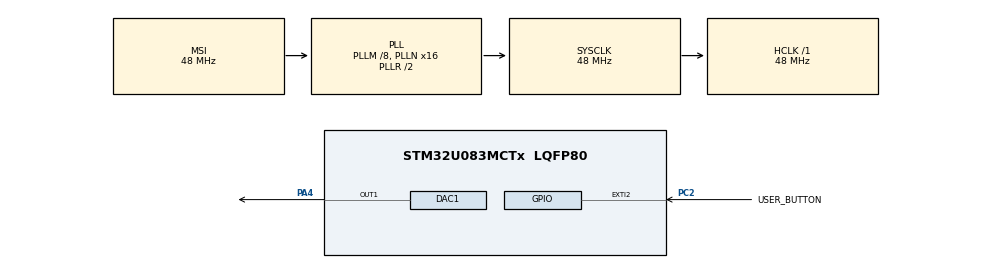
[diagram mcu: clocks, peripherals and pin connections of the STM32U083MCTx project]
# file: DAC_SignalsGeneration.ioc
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DAC1.DAC_Trigger-DAC_OUT1=DAC_TRIGGER_T1_TRGO
Dma.DAC1_CH1.0.Direction=DMA_MEMORY_TO_PERIPH
Dma.DAC1_CH1.0.EventEnable=DISABLE
Dma.DAC1_CH1.0.Instance=DMA1_Channel3
Dma.DAC1_CH1.0.MemDataAlignment=DMA_MDATAALIGN_BYTE
Dma.DAC1_CH1.0.MemInc=DMA_MINC_ENABLE
Dma.DAC1_CH1.0.Mode=DMA_CIRCULAR
Dma.DAC1_CH1.0.PeriphDataAlignment=DMA_PDATAALIGN_BYTE
Dma.DAC1_CH1.0.PeriphInc=DMA_PINC_DISABLE
Dma.DAC1_CH1.0.Polarity=HAL_DMAMUX_REQ_GEN_RISING
Dma.DAC1_CH1.0.Priority=DMA_PRIORITY_LOW
Dma.DAC1_CH1.0.RequestNumber=1
Dma.DAC1_CH1.0.SignalID=NONE
Dma.DAC1_CH1.0.SyncEnable=DISABLE
Dma.DAC1_CH1.0.SyncPolarity=HAL_DMAMUX_SYNC_NO_EVENT
Dma.DAC1_CH1.0.SyncRequestNumber=1
Dma.DAC1_CH1.0.SyncSignalID=NONE
Dma.Request0=DAC1_CH1
Mcu.Family=STM32U0
Mcu.Name=STM32U083MCTx
Mcu.Package=LQFP80
NVIC.DMA1_Channel2_3_IRQn=true\:0\:0\:false\:false\:true\:true\:true\:true
NVIC.EXTI2_3_IRQn=true\:0\:0\:false\:false\:true\:true\:true\:true
NVIC.PriorityGroup=NVIC_PRIORITYGROUP_2
PA4.Signal=COMP_DAC11_group
PC2.GPIO_Label=USER_BUTTON
PC2.GPIO_ModeDefaultEXTI=GPIO_MODE_IT_FALLING
PC2.GPIO_PuPd=GPIO_PULLUP
PC2.Signal=GPXTI2
ProjectManager.HeapSize=0x200
ProjectManager.StackSize=0x400
ProjectManager.TargetToolchain=EWARM V9.20
RCC.ADCFreq_Value=48000000
RCC.AHBFreq_Value=48000000
RCC.CortexFreq_Value=48000000
RCC.HCLKFreq_Value=48000000
RCC.HSE_VALUE=4000000
RCC.HSI48_VALUE=48000000
RCC.HSI_VALUE=16000000
RCC.LSE_VALUE=32768
RCC.MSIClockRangeVal=RCC_MSIRANGE_11
RCC.MSI_VALUE=48000000
RCC.PLLM=RCC_PLLM_DIV8
RCC.PLLN=16
RCC.PLLSourceVirtual=RCC_PLLSOURCE_MSI
RCC.SYSCLKFreq_VALUE=48000000
RCC.SYSCLKSource=RCC_SYSCLKSOURCE_PLLCLK
RCC.USBFreq_Value=48000000
RCC.VCOOutputFreq_Value=96000000
SH.COMP_DAC11_group.0=DAC1_OUT1,DAC_OUT1
TIM1.AutoReloadPreload=TIM_AUTORELOAD_PRELOAD_DISABLE
TIM1.CounterMode=TIM_COUNTERMODE_UP
TIM1.Period=0x7ff
TIM1.Prescaler=0
TIM1.TIM_MasterOutputTrigger=TIM_TRGO_UPDATE
VP_PWR_VS_SECSignals.Mode=Security/Privilege
VP_TIM1_VS_ClockSourceINT.Mode=Internal
board=custom

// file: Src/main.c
/* USER CODE BEGIN Header */
/**
  ******************************************************************************
  * @file    DAC/DAC_SignalsGeneration/Src/main.c
  * @author  MCD Application Team
  * @brief   This example provides a short description of how to use the DAC
  *          peripheral to generate several signals.
  ******************************************************************************
   * @attention
  *
  * Copyright (c) 2023 STMicroelectronics.
  * All rights reserved.
  *
  * This software is licensed under terms that can be found in the LICENSE file
  * in the root directory of this software component.
  * If no LICENSE file comes with this software, it is provided AS-IS.
  *
  ******************************************************************************
  */
/* USER CODE END Header */
#include "main.h"

DAC_HandleTypeDef hdac1;
DMA_HandleTypeDef hdma_dac1_ch1;

TIM_HandleTypeDef htim1;

/* USER CODE BEGIN PV */
__IO uint8_t ubKeyPressed = SET;
__IO uint8_t ubSelectedWavesForm = 1;
const uint8_t aEscalator8bit[6] = {0x0, 0x33, 0x66, 0x99, 0xCC, 0xFF};
/* USER CODE END PV */

void SystemClock_Config(void);
static void MX_GPIO_Init(void);
static void MX_DMA_Init(void);
static void MX_DAC1_Init(void);
static void MX_TIM1_Init(void);
/* USER CODE BEGIN PFP */
static void DAC_Ch1_TriangleConfig(void);
static void DAC_Ch1_EscalatorConfig(void);
/* USER CODE END PFP */

int main(void)
{
  /* USER CODE BEGIN 1 */

  /* STM32U0xx HAL library initialization:
       - Configure the Flash prefetch
       - Systick timer is configured by default as source of time base, but user
         can eventually implement his proper time base source (a general purpose
         timer for example or other time source), keeping in mind that Time base
         duration should be kept 1ms since PPP_TIMEOUT_VALUEs are defined and
         handled in milliseconds basis.
       - Set NVIC Group Priority to 4
       - Low Level Initialization
     */
  /* USER CODE END 1 */

  /* MCU Configuration--------------------------------------------------------*/

  /* Reset of all peripherals, Initializes the Flash interface and the Systick. */
  HAL_Init();

  /* Configure the system clock */
  SystemClock_Config();

  /* Initialize all configured peripherals */
  MX_GPIO_Init();
  MX_DMA_Init();
  MX_DAC1_Init();
  MX_TIM1_Init();
  /* USER CODE BEGIN 2 */
  /* Configure LED5 */
  BSP_LED_Init(LED5);

  /* Configure Joystick Sel push-button in Interrupt mode */
  BSP_PB_Init(BUTTON_USER, BUTTON_MODE_EXTI);

  /* Enable TIM peripheral counter */
  HAL_TIM_Base_Start(&htim1);
  /* USER CODE END 2 */

  /* Infinite loop */
  /* USER CODE BEGIN WHILE */
  while (1)
  {
    /* If the Key is pressed */
    if (ubKeyPressed != RESET)
    {
   HAL_DAC_DeInit(&hdac1);

      /* select waves forms according to the Joystick Sel push-button status */
      if (ubSelectedWavesForm == 1)
      {
        /* The triangle wave has been selected */

        /* Triangle Wave generator -------------------------------------------*/
        DAC_Ch1_TriangleConfig();
      }
      else
      {
        /* The escalator wave has been selected */

        /* Escalator Wave generator -------------------------------------------*/
        DAC_Ch1_EscalatorConfig();
      }

      ubKeyPressed = RESET;
    }
    /* USER CODE END WHILE */

  }
}

void SystemClock_Config(void)
{
  RCC_OscInitTypeDef RCC_OscInitStruct = {0};
  RCC_ClkInitTypeDef RCC_ClkInitStruct = {0};

  /** Configure the main internal regulator output voltage
  */
  HAL_PWREx_ControlVoltageScaling(PWR_REGULATOR_VOLTAGE_SCALE1);

  /** Initializes the RCC Oscillators according to the specified parameters
  * in the RCC_OscInitTypeDef structure.
  */
  RCC_OscInitStruct.OscillatorType = RCC_OSCILLATORTYPE_MSI;
  RCC_OscInitStruct.MSIState = RCC_MSI_ON;
  RCC_OscInitStruct.MSICalibrationValue = RCC_MSICALIBRATION_DEFAULT;
  RCC_OscInitStruct.MSIClockRange = RCC_MSIRANGE_11;
  RCC_OscInitStruct.PLL.PLLState = RCC_PLL_ON;
  RCC_OscInitStruct.PLL.PLLSource = RCC_PLLSOURCE_MSI;
  RCC_OscInitStruct.PLL.PLLM = RCC_PLLM_DIV8;
  RCC_OscInitStruct.PLL.PLLN = 16;
  RCC_OscInitStruct.PLL.PLLP = RCC_PLLP_DIV2;
  RCC_OscInitStruct.PLL.PLLQ = RCC_PLLQ_DIV2;
  RCC_OscInitStruct.PLL.PLLR = RCC_PLLR_DIV2;
  if (HAL_RCC_OscConfig(&RCC_OscInitStruct) != HAL_OK)
  {
    Error_Handler();
  }

  /** Initializes the CPU, AHB and APB buses clocks
  */
  RCC_ClkInitStruct.ClockType = RCC_CLOCKTYPE_HCLK|RCC_CLOCKTYPE_SYSCLK
                              |RCC_CLOCKTYPE_PCLK1;
  RCC_ClkInitStruct.SYSCLKSource = RCC_SYSCLKSOURCE_PLLCLK;
  RCC_ClkInitStruct.AHBCLKDivider = RCC_SYSCLK_DIV1;
  RCC_ClkInitStruct.APB1CLKDivider = RCC_HCLK_DIV1;

  if (HAL_RCC_ClockConfig(&RCC_ClkInitStruct, FLASH_LATENCY_1) != HAL_OK)
  {
    Error_Handler();
  }
}

static void MX_DAC1_Init(void)
{

  DAC_ChannelConfTypeDef sConfig = {0};

  /** DAC Initialization
  */
  hdac1.Instance = DAC1;
  if (HAL_DAC_Init(&hdac1) != HAL_OK)
  {
    Error_Handler();
  }

  /** DAC channel OUT1 config
  */
  sConfig.DAC_SampleAndHold = DAC_SAMPLEANDHOLD_DISABLE;
  sConfig.DAC_Trigger = DAC_TRIGGER_T1_TRGO;
  sConfig.DAC_OutputBuffer = DAC_OUTPUTBUFFER_DISABLE;
  sConfig.DAC_ConnectOnChipPeripheral = DAC_CHIPCONNECT_EXTERNAL;
  sConfig.DAC_UserTrimming = DAC_TRIMMING_FACTORY;
  if (HAL_DAC_ConfigChannel(&hdac1, &sConfig, DAC_CHANNEL_1) != HAL_OK)
  {
    Error_Handler();
  }

}

static void MX_TIM1_Init(void)
{

  TIM_ClockConfigTypeDef sClockSourceConfig = {0};
  TIM_MasterConfigTypeDef sMasterConfig = {0};

  htim1.Instance = TIM1;
  htim1.Init.Prescaler = 0;
  htim1.Init.CounterMode = TIM_COUNTERMODE_UP;
  htim1.Init.Period = 0x7ff;
  htim1.Init.ClockDivision = TIM_CLOCKDIVISION_DIV1;
  htim1.Init.RepetitionCounter = 0;
  htim1.Init.AutoReloadPreload = TIM_AUTORELOAD_PRELOAD_DISABLE;
  if (HAL_TIM_Base_Init(&htim1) != HAL_OK)
  {
    Error_Handler();
  }
  sClockSourceConfig.ClockSource = TIM_CLOCKSOURCE_INTERNAL;
  if (HAL_TIM_ConfigClockSource(&htim1, &sClockSourceConfig) != HAL_OK)
  {
    Error_Handler();
  }
  sMasterConfig.MasterOutputTrigger = TIM_TRGO_UPDATE;
  sMasterConfig.MasterOutputTrigger2 = TIM_TRGO2_RESET;
  sMasterConfig.MasterSlaveMode = TIM_MASTERSLAVEMODE_DISABLE;
  if (HAL_TIMEx_MasterConfigSynchronization(&htim1, &sMasterConfig) != HAL_OK)
  {
    Error_Handler();
  }

}

static void MX_DMA_Init(void)
{

  /* DMA controller clock enable */
  __HAL_RCC_DMA1_CLK_ENABLE();

  /* DMA interrupt init */
  /* DMA1_Channel2_3_IRQn interrupt configuration */
  HAL_NVIC_SetPriority(DMA1_Channel2_3_IRQn, 0, 0);
  HAL_NVIC_EnableIRQ(DMA1_Channel2_3_IRQn);

}

static void MX_GPIO_Init(void)
{
  GPIO_InitTypeDef GPIO_InitStruct = {0};

  /* GPIO Ports Clock Enable */
  __HAL_RCC_GPIOC_CLK_ENABLE();
  __HAL_RCC_GPIOA_CLK_ENABLE();

  /*Configure GPIO pin : USER_BUTTON_Pin */
  GPIO_InitStruct.Pin = USER_BUTTON_Pin;
  GPIO_InitStruct.Mode = GPIO_MODE_IT_FALLING;
  GPIO_InitStruct.Pull = GPIO_PULLUP;
  HAL_GPIO_Init(USER_BUTTON_GPIO_Port, &GPIO_InitStruct);

  /* EXTI interrupt init*/
  HAL_NVIC_SetPriority(EXTI2_3_IRQn, 0, 0);
  HAL_NVIC_EnableIRQ(EXTI2_3_IRQn);

}

/* USER CODE BEGIN 4 */
/**
  * @brief  DAC Channel1 EscalatorConfig
  * @param  None
  * @retval None
  */
static void DAC_Ch1_EscalatorConfig(void)
{
  /*##-1- Initialize the DAC peripheral ######################################*/
  if (HAL_DAC_Init(&hdac1) != HAL_OK)
  {
    /* DAC initialization Error */
    Error_Handler();
  }

  /*##-2- Enable DAC selected channel and associated DMA ######################*/
  if (HAL_DAC_Start_DMA(&hdac1, DAC_CHANNEL_1, (uint32_t *)aEscalator8bit, 6, DAC_ALIGN_8B_R) != HAL_OK)
  {
    /* Start DMA Error */
    Error_Handler();
  }
}

/**
  * @brief  DAC Channel1 Triangle Configuration
  * @param  None
  * @retval None
  */
static void DAC_Ch1_TriangleConfig(void)
{
  /*##-1- Initialize the DAC peripheral ######################################*/
  if (HAL_DAC_Init(&hdac1) != HAL_OK)
  {
    /* DAC initialization Error */
    Error_Handler();
  }

  /*##-2- DAC channel2 Triangle Wave generation configuration ################*/
  if (HAL_DACEx_TriangleWaveGenerate(&hdac1, DAC_CHANNEL_1, DAC_TRIANGLEAMPLITUDE_1023) != HAL_OK)
  {
    /* Triangle wave generation Error */
    Error_Handler();
  }

  /*##-3- Enable DAC Channel1 ################################################*/
  if (HAL_DAC_Start(&hdac1, DAC_CHANNEL_1) != HAL_OK)
  {
    /* Start Error */
    Error_Handler();
  }

  /*##-4- Set DAC channel1 DHR12RD register ################################################*/
  if (HAL_DAC_SetValue(&hdac1, DAC_CHANNEL_1, DAC_ALIGN_12B_R, 0x100) != HAL_OK)
  {
    /* Setting value Error */
    Error_Handler();
  }
}

/**
  * @brief EXTI line detection callbacks
  * @param GPIO_Pin: Specifies the pins connected EXTI line
  * @retval None
  */
void HAL_GPIO_EXTI_Rising_Callback(uint16_t GPIO_Pin)
{
  /* Change the wave */
  if (GPIO_Pin == JOY1_SEL_PIN)
  {
    ubKeyPressed = 1;
  }
  /* Change the selected waves forms */
  ubSelectedWavesForm = !ubSelectedWavesForm;
}

/* USER CODE END 4 */

void Error_Handler(void)
{
  /* USER CODE BEGIN Error_Handler_Debug */
  /* Turn LED5 on */
  BSP_LED_On(LED5);
  while(1)
  {
  }
  /* USER CODE END Error_Handler_Debug */
}
